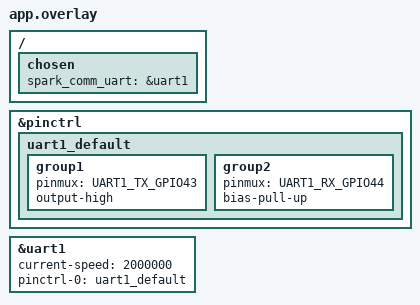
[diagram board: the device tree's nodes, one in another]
/*
 * DeviceTree Overlay for ESP32-S3 Super Mini Wi-Fi Audio Streaming Co-Processor
 *
 * Board: ESP32-S3 Super Mini (ESP32-S3FH4R2, 4MB Flash, 2MB PSRAM)
 * Outer Side Pin Header Assignments:
 *   - Pin labeled "TX" (GPIO 43) -> High-Speed UART1 TX to RT-Spark (PA3 / Pin 10)
 *   - Pin labeled "RX" (GPIO 44) -> High-Speed UART1 RX to RT-Spark (PA2 / Pin 8)
 *   - Pin labeled "GND"          -> Ground to RT-Spark (GND / Pin 4, 6, or 9)
 *   - Pin labeled "5V"           -> Power from RT-Spark (5V / Pin 2)
 */

#include <zephyr/dt-bindings/pinctrl/esp-pinctrl-common.h>
#include <zephyr/dt-bindings/pinctrl/esp32s3-pinctrl.h>

/ {
	chosen {
		spark_comm_uart = &uart1;
	};
};

&pinctrl {
	uart1_default: uart1_default {
		group1 {
			pinmux = <UART1_TX_GPIO43>;
			output-high;
		};

		group2 {
			pinmux = <UART1_RX_GPIO44>;
			bias-pull-up;
		};
	};
};

&uart1 {
	status = "okay";
	current-speed = <2000000>;
	pinctrl-0 = <&uart1_default>;
	pinctrl-names = "default";
};
